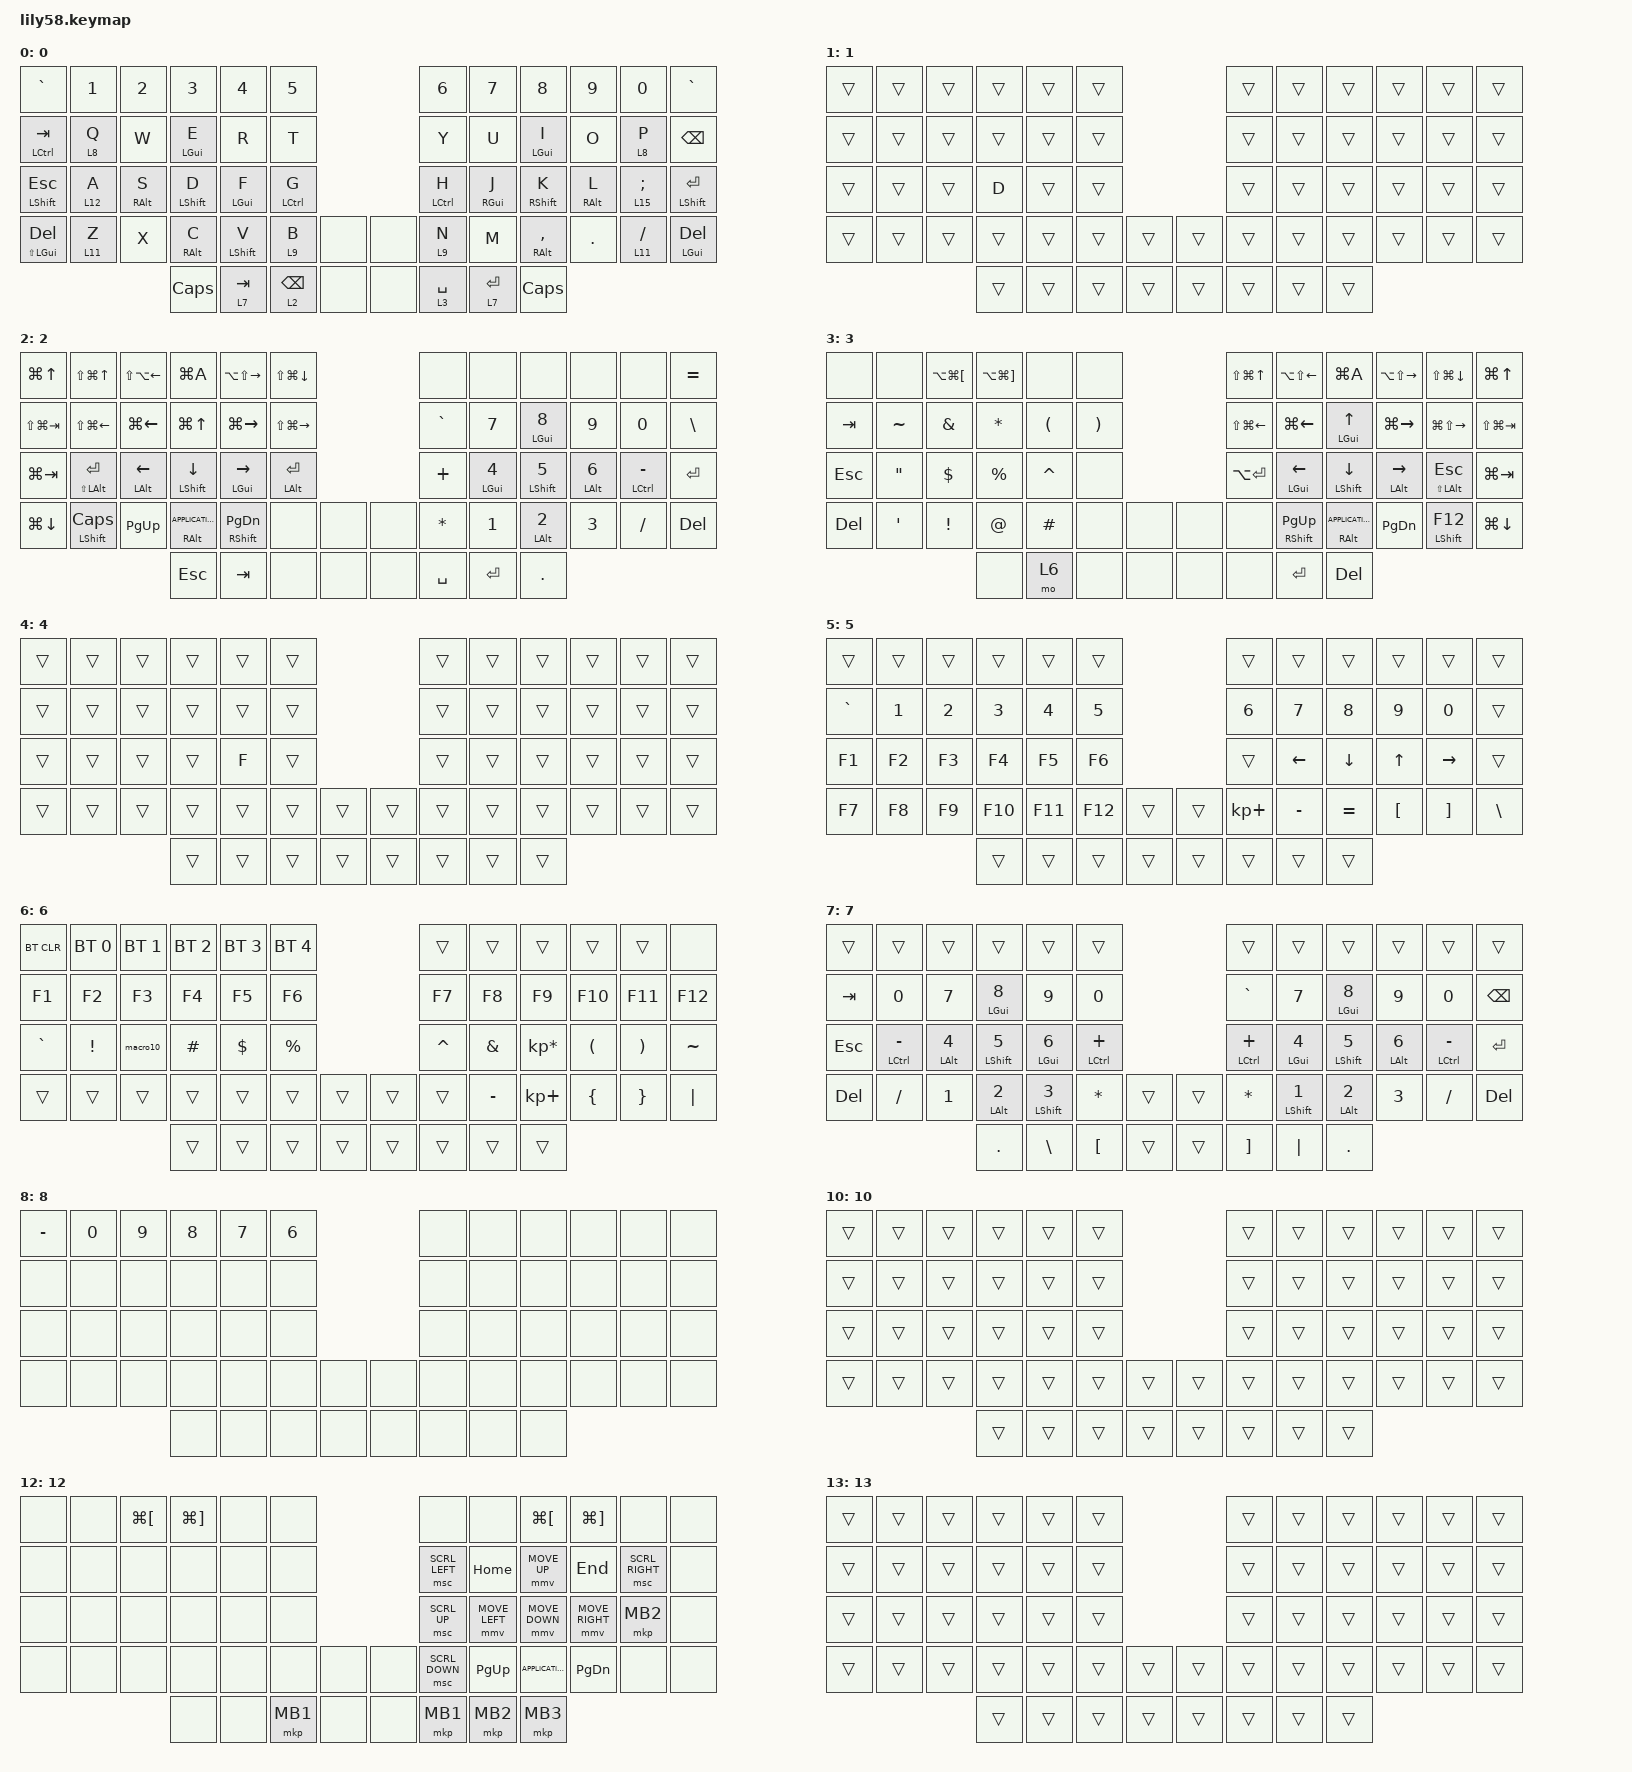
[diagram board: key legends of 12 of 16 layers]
/*
 * Copyright (c) 2020 The ZMK Contributors
 *
 * SPDX-License-Identifier: MIT
 */

#define ZMK_POINTING_DEFAULT_MOVE_VAL 900  // 기본 600
#define ZMK_POINTING_DEFAULT_SCRL_VAL 15    // 기본 10

#include <behaviors.dtsi>
#include <dt-bindings/zmk/bt.h>
#include <dt-bindings/zmk/keys.h>
#include <dt-bindings/zmk/pointing.h>

/ {
    combos {
        compatible = "zmk,combos";

        MOD_ES {
            bindings = <&kp DELETE>;
            key-positions = <14 52>;
        };

        MOD_EN {
            bindings = <&kp ENTER>;
            key-positions = <15 52>;
            require-prior-idle-ms = <100>;
        };

        MOD_SP {
            bindings = <&kp SPACE>;
            key-positions = <16 52>;
            require-prior-idle-ms = <100>;
        };

        paste {
            bindings = <&kp LG(V)>;
            key-positions = <52 28>;
            require-prior-idle-ms = <100>;
        };

        copy {
            bindings = <&kp LG(C)>;
            key-positions = <27 52>;
            require-prior-idle-ms = <100>;
        };

        cut {
            bindings = <&kp LG(X)>;
            key-positions = <26 52>;
            require-prior-idle-ms = <100>;
        };

        AltTab {
            bindings = <&kp LG(TAB)>;
            key-positions = <25 52>;
            require-prior-idle-ms = <100>;
        };

        Lan_LH {
            bindings = <&kp LC(SPACE)>;
            key-positions = <52 40>;
        };

        W_ {
            bindings = <&kp LS(W)>;
            key-positions = <14 15>;
            layers = <0 1>;
        };

        R_ {
            bindings = <&kp LS(R)>;
            key-positions = <15 16>;
            layers = <0 1>;
        };

        T_ {
            bindings = <&kp LS(T)>;
            key-positions = <27 28>;
            layers = <0 1>;
        };

        E_ {
            bindings = <&kp LS(E)>;
            key-positions = <27 26>;
            layers = <0 1>;
        };

        P_ {
            bindings = <&kp LS(P)>;
            key-positions = <34 33>;
            layers = <0 1>;
        };

        b_ {
            bindings = <&kp B>;
            key-positions = <32 33>;
            layers = <0 1>;
        };

        Lan_RH {
            bindings = <&kp LC(SPACE)>;
            key-positions = <31 32>;
        };

        MOD_BS {
            bindings = <&kp BACKSPACE>;
            key-positions = <55 19>;
            require-prior-idle-ms = <100>;
        };

        MOD_TA {
            bindings = <&kp TAB>;
            key-positions = <55 20>;
            require-prior-idle-ms = <100>;
        };

        MOD_ESC {
            bindings = <&kp ESCAPE>;
            key-positions = <55 21>;
            require-prior-idle-ms = <100>;
        };

        Q_ {
            bindings = <&kp LS(Q)>;
            key-positions = <26 25>;
        };
    };

    macros {
        macro10: macro10 {
            compatible = "zmk,behavior-macro";
            #binding-cells = <0>;
            bindings = <&kp N6 &kp N0 &kp N0 &kp N6 &kp N2 &kp N2 &kp N6>;
            label = "MACRO10";
        };
    };

    behaviors {
        hmMT: hmMT {
            compatible = "zmk,behavior-hold-tap";
            label = "HMMT";
            bindings = <&mt>, <&kp>;

            #binding-cells = <2>;
            tapping-term-ms = <250>;
            flavor = "tap-preferred";
        };

        hmLT: hmLT {
            compatible = "zmk,behavior-hold-tap";
            label = "HMLT";
            bindings = <&mo>, <&kp>;

            #binding-cells = <2>;
            tapping-term-ms = <250>;
            flavor = "tap-preferred";
        };
    };

    keymap {
        compatible = "zmk,keymap";

        layer_0 {
            display-name = "0";
            bindings = <
&kp GRAVE             &kp N1      &kp N2        &kp N3           &kp N4              &kp N5                           &kp N6         &kp N7        &kp N8                 &kp N9             &kp N0              &kp GRAVE
&mt LEFT_CONTROL TAB  &hmLT 8 Q   &kp W         &hmMT LGUI E     &kp R               &kp T                            &kp Y          &kp U         &hmMT LGUI I           &kp O              &hmLT 8 P           &kp BACKSPACE
&mt LSHIFT ESCAPE     &hmLT 12 A  &hmMT RALT S  &hmMT LSHIFT D   &hmMT LGUI F        &hmMT LCTRL G                    &hmMT LCTRL H  &hmMT RGUI J  &hmMT RSHIFT K         &hmMT RIGHT_ALT L  &hmLT 15 SEMICOLON  &mt LSHIFT ENTER
&mt LS(LGUI) DELETE   &hmLT 11 Z  &kp X         &mt RIGHT_ALT C  &hmMT LEFT_SHIFT V  &hmLT 9 B        &none    &none  &hmLT 9 N      &kp M         &hmMT RIGHT_ALT COMMA  &kp DOT            &hmLT 11 SLASH      &mt LGUI DELETE
                                                &kp CAPS         &lt 7 TAB           &lt 2 BACKSPACE  &none    &none  &lt 3 SPACE    &lt 7 ENTER   &kp CAPS
            >;
        };

        layer_1 {
            bindings = <
&trans  &trans  &trans  &trans  &trans  &trans                    &trans  &trans  &trans  &trans  &trans  &trans
&trans  &trans  &trans  &trans  &trans  &trans                    &trans  &trans  &trans  &trans  &trans  &trans
&trans  &trans  &trans  &kp D   &trans  &trans                    &trans  &trans  &trans  &trans  &trans  &trans
&trans  &trans  &trans  &trans  &trans  &trans  &trans    &trans  &trans  &trans  &trans  &trans  &trans  &trans
                        &trans  &trans  &trans  &trans    &trans  &trans  &trans  &trans
            >;

            label = "1";
        };

        layer_2 {
            bindings = <
&kp LG(UP)       &kp LS(LG(UP))          &kp LS(LA(LEFT))   &kp LG(A)                    &kp LA(LS(RIGHT))     &kp LS(LG(DOWN))                    &none         &none        &none            &none        &none            &kp EQUAL
&kp LS(LG(TAB))  &kp LS(LG(LEFT))        &kp LG(LEFT)       &kp LG(UP)                   &kp LG(RIGHT)         &kp LS(LG(RIGHT))                   &kp GRAVE     &kp N7       &mt LGUI N8      &kp N9       &kp N0           &kp BACKSLASH
&kp LG(TAB)      &mt LS(LEFT_ALT) ENTER  &mt LEFT_ALT LEFT  &mt LSHIFT DOWN              &mt LGUI RIGHT        &mt LEFT_ALT ENTER                  &kp PLUS      &mt LGUI N4  &mt LSHFT N5     &mt LALT N6  &mt LCTRL MINUS  &kp ENTER
&kp LG(DOWN)     &mt LSHIFT CAPS         &kp PAGE_UP        &mt RIGHT_ALT K_APPLICATION  &mt RSHIFT PAGE_DOWN  &none               &none    &none  &kp ASTERISK  &kp N1       &mt LEFT_ALT N2  &kp N3       &kp SLASH        &kp DELETE
                                                            &kp ESCAPE                   &kp TAB               &none               &none    &none  &kp SPACE     &kp ENTER    &kp DOT
            >;

            label = "2";
        };

        layer_3 {
            bindings = <
&none       &none              &kp LA(LG(LEFT_BRACKET))  &kp LA(LG(RIGHT_BRACKET))  &none                 &none                                  &kp LS(LG(UP_ARROW))  &kp LA(LS(LEFT))    &kp LG(A)                    &kp LA(LS(RIGHT))   &kp LS(LG(DOWN))         &kp LG(UP)
&kp TAB     &kp TILDE          &kp AMPERSAND             &kp ASTERISK               &kp LEFT_PARENTHESIS  &kp RIGHT_PARENTHESIS                  &kp LS(LG(LEFT))      &kp LG(LEFT)        &mt LGUI UP                  &kp LG(RIGHT)       &kp LG(LS(RIGHT))        &kp LS(LG(TAB))
&kp ESCAPE  &kp DOUBLE_QUOTES  &kp DOLLAR                &kp PERCENT                &kp CARET             &none                                  &kp LA(ENTER)         &mt LGUI LEFT       &mt LSHIFT DOWN              &mt LEFT_ALT RIGHT  &mt LS(LEFT_ALT) ESCAPE  &kp LG(TAB)
&kp DELETE  &kp SQT            &kp EXCLAMATION           &kp AT_SIGN                &kp HASH              &none                  &none    &none  &none                 &mt RSHIFT PAGE_UP  &mt RIGHT_ALT K_APPLICATION  &kp PAGE_DOWN       &mt LSHIFT F12           &kp LG(DOWN)
                                                         &none                      &mo 6                 &none                  &none    &none  &none                 &kp ENTER           &kp DELETE
            >;

            label = "3";
        };

        layer_4 {
            bindings = <
&trans  &trans  &trans  &trans  &trans  &trans                    &trans  &trans  &trans  &trans  &trans  &trans
&trans  &trans  &trans  &trans  &trans  &trans                    &trans  &trans  &trans  &trans  &trans  &trans
&trans  &trans  &trans  &trans  &kp F   &trans                    &trans  &trans  &trans  &trans  &trans  &trans
&trans  &trans  &trans  &trans  &trans  &trans  &trans    &trans  &trans  &trans  &trans  &trans  &trans  &trans
                        &trans  &trans  &trans  &trans    &trans  &trans  &trans  &trans
            >;

            label = "4";
        };

        layer_5 {
            display-name = "5";
            bindings = <
&trans     &trans  &trans  &trans   &trans   &trans                     &trans       &trans     &trans     &trans    &trans     &trans
&kp GRAVE  &kp N1  &kp N2  &kp N3   &kp N4   &kp N5                     &kp N6       &kp N7     &kp N8     &kp N9    &kp N0     &trans
&kp F1     &kp F2  &kp F3  &kp F4   &kp F5   &kp F6                     &trans       &kp LEFT   &kp DOWN   &kp UP    &kp RIGHT  &trans
&kp F7     &kp F8  &kp F9  &kp F10  &kp F11  &kp F12  &trans    &trans  &kp KP_PLUS  &kp MINUS  &kp EQUAL  &kp LBKT  &kp RBKT   &kp BSLH
                           &trans   &trans   &trans   &trans    &trans  &trans       &trans     &trans
            >;

            sensor-bindings = <&inc_dec_kp C_VOL_UP C_VOL_DN>;
        };

        layer_6 {
            display-name = "6";
            bindings = <
&bt BT_CLR  &bt BT_SEL 0  &bt BT_SEL 1  &bt BT_SEL 2  &bt BT_SEL 3  &bt BT_SEL 4                    &trans     &trans     &trans           &trans    &trans    &none
&kp F1      &kp F2        &kp F3        &kp F4        &kp F5        &kp F6                          &kp F7     &kp F8     &kp F9           &kp F10   &kp F11   &kp F12
&kp GRAVE   &kp EXCL      &macro10      &kp HASH      &kp DOLLAR    &kp PRCNT                       &kp CARET  &kp AMPS   &kp KP_MULTIPLY  &kp LPAR  &kp RPAR  &kp TILDE
&trans      &trans        &trans        &trans        &trans        &trans        &trans    &trans  &trans     &kp MINUS  &kp KP_PLUS      &kp LBRC  &kp RBRC  &kp PIPE
                                        &trans        &trans        &trans        &trans    &trans  &trans     &trans     &trans
            >;

            sensor-bindings = <&inc_dec_kp C_VOL_UP C_VOL_DN>;
        };

        layer_7 {
            bindings = <
&trans   &trans           &trans           &trans         &trans         &trans                            &trans          &trans         &trans         &trans       &trans           &trans
&kp TAB  &kp N0           &kp N7           &mt LGUI N8    &kp N9         &kp N0                            &kp GRAVE       &kp N7         &mt LGUI N8    &kp N9       &kp N0           &kp BSPC
&kp ESC  &mt LCTRL MINUS  &mt LEFT_ALT N4  &mt LSHIFT N5  &mt LGUI N6    &mt LCTRL PLUS                    &mt LCTRL PLUS  &mt LGUI N4    &mt LSHIFT N5  &mt LALT N6  &mt LCTRL MINUS  &kp RET
&kp DEL  &kp FSLH         &kp N1           &mt LALT N2    &mt LSHIFT N3  &kp ASTERISK    &trans    &trans  &kp ASTERISK    &mt LSHIFT N1  &mt LALT N2    &kp N3       &kp FSLH         &kp DEL
                                           &kp DOT        &kp BSLH       &kp LBKT        &trans    &trans  &kp RBKT        &kp PIPE       &kp DOT
            >;

            label = "7";
        };

        layer_8 {
            bindings = <
&kp MINUS  &kp N0  &kp N9  &kp N8  &kp N7  &kp NUMBER_6                  &none  &none  &none  &none  &none  &none
&none      &none   &none   &none   &none   &none                         &none  &none  &none  &none  &none  &none
&none      &none   &none   &none   &none   &none                         &none  &none  &none  &none  &none  &none
&none      &none   &none   &none   &none   &none         &none    &none  &none  &none  &none  &none  &none  &none
                           &none   &none   &none         &none    &none  &none  &none  &none
            >;

            label = "8";
        };

        layer_9 {
            bindings = <
&trans                   &trans  &trans  &trans  &trans  &trans                    &trans  &trans  &trans  &trans  &trans  &trans
&kp LS(LA(LC(LG(F13))))  &trans  &trans  &trans  &trans  &trans                    &trans  &trans  &trans  &trans  &trans  &trans
&trans                   &trans  &trans  &trans  &trans  &trans                    &trans  &trans  &trans  &trans  &trans  &trans
&trans                   &trans  &trans  &trans  &trans  &trans  &trans    &trans  &trans  &trans  &trans  &trans  &trans  &trans
                                         &trans  &trans  &trans  &trans    &trans  &trans  &trans  &trans
            >;

            label = "9";
        };

        layer_10 {
            bindings = <
&trans  &trans  &trans  &trans  &trans  &trans                    &trans  &trans  &trans  &trans  &trans  &trans
&trans  &trans  &trans  &trans  &trans  &trans                    &trans  &trans  &trans  &trans  &trans  &trans
&trans  &trans  &trans  &trans  &trans  &trans                    &trans  &trans  &trans  &trans  &trans  &trans
&trans  &trans  &trans  &trans  &trans  &trans  &trans    &trans  &trans  &trans  &trans  &trans  &trans  &trans
                        &trans  &trans  &trans  &trans    &trans  &trans  &trans  &trans
            >;

            label = "10";
        };

        layer_11 {
            bindings = <
&kp MINUS     &kp N0         &kp N9      &kp N8                   &kp N7                  &kp N6                                  &kp N5                  &kp N4                  &kp N3                   &kp N2  &kp N1  &kp GRAVE
&none         &kp P          &kp O       &kp I                    &kp U                   &kp Y                                   &kp T                   &kp R                   &kp E                    &kp W   &kp Q   &none
&kp LG(RBKT)  &kp SEMICOLON  &kp L       &kp K                    &kp J                   &kp H                                   &kp G                   &kp F                   &kp D                    &kp S   &kp A   &kp LG(RBKT)
&kp LG(LBKT)  &kp SLASH      &kp PERIOD  &kp COMMA                &kp M                   &kp N                   &none    &none  &kp B                   &kp V                   &kp C                    &kp X   &kp Z   &kp LG(LBKT)
                                         &kp LS(LA(LC(LG(F19))))  &kp LS(LA(LC(LG(F4))))  &kp LS(LA(LC(LG(F6))))  &none    &none  &kp LS(LA(LC(LG(F4))))  &kp LS(LA(LC(LG(F6))))  &kp LS(LA(LC(LG(F22))))
            >;

            label = "11";
        };

        layer_12 {
            bindings = <
&none  &none  &kp LG(LBKT)  &kp LG(RBKT)  &none  &none                     &none           &none           &kp LG(LBKT)       &kp LG(RBKT)     &none            &none
&none  &none  &none         &none         &none  &none                     &msc SCRL_LEFT  &kp HOME        &mmv MOVE_UP       &kp END          &msc SCRL_RIGHT  &none
&none  &none  &none         &none         &none  &none                     &msc SCRL_UP    &mmv MOVE_LEFT  &mmv MOVE_DOWN     &mmv MOVE_RIGHT  &mkp MB2         &none
&none  &none  &none         &none         &none  &none     &none    &none  &msc SCRL_DOWN  &kp PAGE_UP     &kp K_APPLICATION  &kp PAGE_DOWN    &none            &none
                            &none         &none  &mkp MB1  &none    &none  &mkp MB1        &mkp MB2        &mkp MB3
            >;

            label = "12";
        };

        layer_13 {
            bindings = <
&trans  &trans  &trans  &trans  &trans  &trans                    &trans  &trans  &trans  &trans  &trans  &trans
&trans  &trans  &trans  &trans  &trans  &trans                    &trans  &trans  &trans  &trans  &trans  &trans
&trans  &trans  &trans  &trans  &trans  &trans                    &trans  &trans  &trans  &trans  &trans  &trans
&trans  &trans  &trans  &trans  &trans  &trans  &trans    &trans  &trans  &trans  &trans  &trans  &trans  &trans
                        &trans  &trans  &trans  &trans    &trans  &trans  &trans  &trans
            >;

            label = "13";
        };

        layer_14 {
            bindings = <
&trans  &trans  &trans  &trans  &trans  &trans                    &trans  &trans  &trans  &trans  &trans  &trans
&trans  &trans  &trans  &trans  &trans  &trans                    &trans  &trans  &trans  &trans  &trans  &trans
&trans  &trans  &trans  &trans  &trans  &trans                    &trans  &trans  &trans  &trans  &trans  &trans
&trans  &trans  &trans  &trans  &trans  &trans  &trans    &trans  &trans  &trans  &trans  &trans  &trans  &trans
                        &trans  &trans  &trans  &trans    &trans  &trans  &trans  &trans
            >;

            label = "14";
        };

        layer_15 {
            bindings = <
&kp GRAVE  &kp N1     &kp N2     &kp N3     &kp N4     &kp N5                     &kp N6            &kp N7     &kp N8     &kp N9     &kp N0     &kp MINUS
&kp TAB    &kp LA(Q)  &kp LA(W)  &kp LA(E)  &kp LA(R)  &kp LA(T)                  &kp LA(Y)         &kp LA(U)  &kp LA(I)  &kp LA(O)  &kp LA(P)  &kp BSPC
&kp ESC    &kp LA(A)  &kp LA(S)  &kp LA(D)  &kp LA(F)  &kp LA(G)                  &kp LA(H)         &kp LA(J)  &kp LA(K)  &kp LA(L)  &none      &kp RET
&kp DEL    &kp LA(Z)  &kp LA(X)  &kp LA(C)  &kp LA(V)  &kp LA(B)  &none    &none  &kp LA(N)         &kp LA(M)  &kp COMMA  &kp DOT    &kp FSLH   &kp DEL
                                 &kp ESC    &kp TAB    &kp BSPC   &none    &none  &mt LSHIFT SPACE  &kp ENTER  &kp DEL
            >;

            label = "15";
        };
    };

    conditional_layers { compatible = "zmk,conditional-layers"; };
};
